AUTOSAR XML (schema 4-0-3)
package /ErrM/ApplicationSwComponentTypes
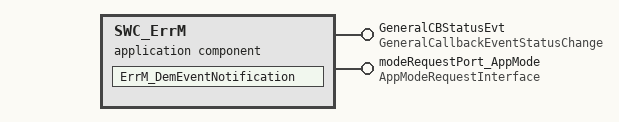
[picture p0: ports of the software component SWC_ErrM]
  application sw component type SWC_ErrM
    provide port GeneralCBStatusEvt: server-com-spec{operation=EventStatusChanged, queue-length=1}, provided-interface=GeneralCallbackEventStatusChange
    provide port modeRequestPort_AppMode: nonqueued-sender-com-spec=AppMode, provided-interface=AppModeRequestInterface
    behavior SwcIB_ErrM: data-type-mapping=MAP_AppMode, included-data-type-set=data-type=[Dem_EventStatusType, Dem_EventIdType, Dem_EventStatusExtendedType]
      operation invoked event OIE_GeneralCallbackEventStatusChange: start-on-event=ErrM_DemEventNotification, operation=GeneralCBStatusEvt.EventStatusChanged
      runnable ErrM_DemEventNotification
        data-send-points:
          access DSP_ErrM_DemEventNotification_modeRequestPort_AppMode_AppMode: accessed-variable=modeRequestPort_AppMode.AppMode, scope=COMMUNICATION-INTER-ECU
